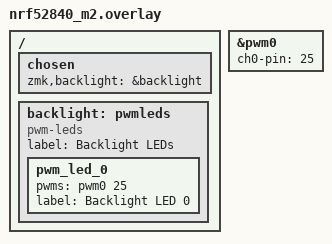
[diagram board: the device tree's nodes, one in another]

/ {
    chosen {
        zmk,backlight = &backlight;
    };
    backlight: pwmleds {
        compatible = "pwm-leds";
        label = "Backlight LEDs";
        pwm_led_0 {
            pwms = <&pwm0 25>;
            label = "Backlight LED 0";
        };
    };
};

&pwm0 {
    status = "okay";
    ch0-pin = <25>;
    /* ch0-inverted; */
};
